# LPC111x/LPC11Cxx/LPC11xxL/LPC11xxXL register map
File version: 6
CPU: CM0 r0p0, little endian, no MPU, no FPU, 2 interrupt priority bits
Registers are 32-bit, read-write, reset 0x0 unless marked. A register's access mark holds for its fields unless they carry their own. Offsets are from the block's base; [hi:lo] are bit positions; {n}, {i} and the like mark numbered series.

## FLASHCTRL — Flash Programming Firmware
Base 0x4003C000
0x10 FLASHCFG reset not defined — Flash memory access time configuration register
  [1:0] FLASHTIM — Flash memory access time. FLASHTIM +1 is equal to the number of system clocks used for flash access.
    1=1_SYSTEM_CLOCK_FLASH (1 system clock flash access time (for system clock frequencies of up to 20 MHz)); 2=2_SYSTEM_CLOCKS_FLAS (2 system clocks flash access time (for system clock frequencies of up to 40 MHz)); 3=3_SYSTEM_CLOCKS_FLAS (3 system clocks flash access time (for system clock frequencies of up to 50 MHz))
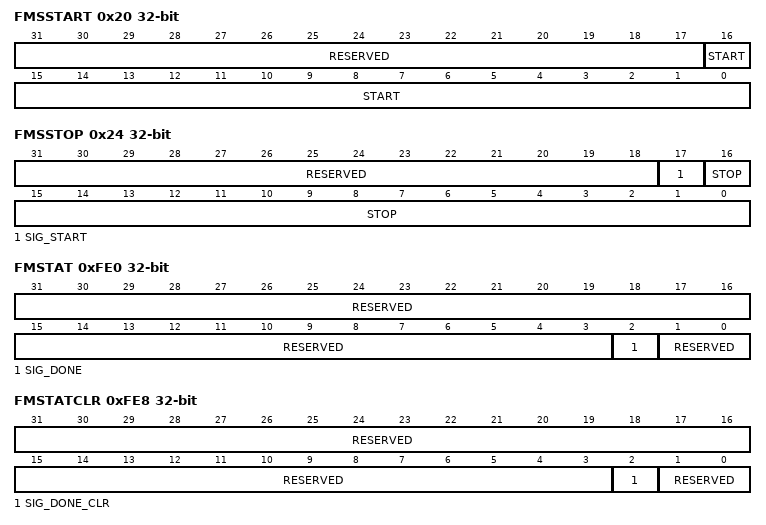
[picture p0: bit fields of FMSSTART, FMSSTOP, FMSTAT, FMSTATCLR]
0x20 FMSSTART — Signature start address register
  [31:17] RESERVED — Reserved, user software should not write ones to reserved bits. The value read from a reserved bit is not defined.
  [16:0] START — Signature generation start address (corresponds to AHB byte address bits[20:4]).
0x24 FMSSTOP — Signature stop-address register
  [31:18] RESERVED — Reserved, user software should not write ones to reserved bits. The value read from a reserved bit is not defined.
  [17] SIG_START — Start control bit for signature generation.
    0=SIGNATURE_GENERATION (Signature generation is stopped); 1=INITIATE_SIGNATURE_G (Initiate signature generation)
  [16:0] STOP — BIST stop address divided by 16 (corresponds to AHB byte address [20:4]).
{0x2C+4i} FMSW{i} ro reset not defined (i=0..3) — Word {i} [{32i+31}:{32i}]
  [31:0] SW{i}_{32i+31}_{32i} — Word {i} of 128-bit signature (bits {32i+31} to {32i}).
0xFE0 FMSTAT ro — Signature generation status register
  [31:3] RESERVED — Reserved, user software should not write ones to reserved bits. The value read from a reserved bit is not defined.
  [2] SIG_DONE — When 1, a previously started signature generation has completed. See FMSTATCLR register description for clearing this flag.
  [1:0] RESERVED — Reserved, user software should not write ones to reserved bits. The value read from a reserved bit is not defined.
0xFE8 FMSTATCLR wo reset not defined — Signature generation status clear register
  [31:3] RESERVED — Reserved, user software should not write ones to reserved bits. The value read from a reserved bit is not defined.
  [2] SIG_DONE_CLR — Writing a 1 to this bits clears the signature generation completion flag (SIG_DONE) in the FMSTAT register.
  [1:0] RESERVED — Reserved, user software should not write ones to reserved bits. The value read from a reserved bit is not defined.

## GPIO0 — General Purpose I/O
Base 0x50000000
Same registers: GPIO1 0x50010000, GPIO2 0x50020000, GPIO3 0x50030000
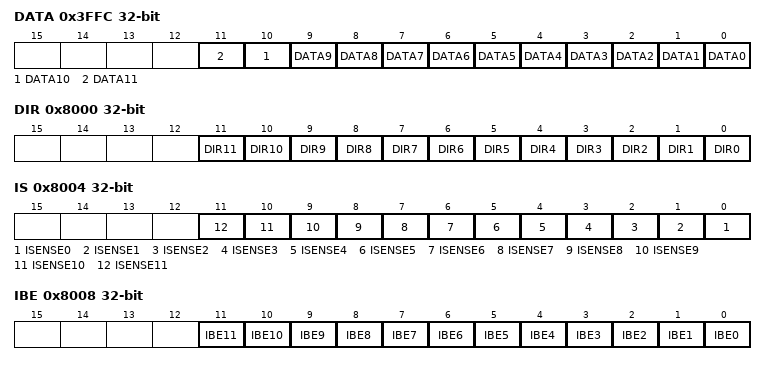
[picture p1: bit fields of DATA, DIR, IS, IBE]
0x3FFC DATA reset not defined
  [all] fields
    0=LOW (Pin is driven low); 1=HIGH (Pin is driven high)
  [n] DATA{n} (n=0..11) — PIOn_{n}.
0x8000 DIR — Data direction register
  [all] fields
    0=INPUT (Pin is configured as an input); 1=OUTPUT (Pin is configured as an output)
  [n] DIR{n} (n=0..11) — PIOn_{n}.
0x8004 IS — Interrupt sense register
  [all] fields
    0=EDGE (Pin interrupt is edge-sensitive); 1=LEVEL (Pin interrupt is level-sensitive)
  [n] ISENSE{n} (n=0..11) — PIOn_{n}.
0x8008 IBE — Interrupt both-edges register
  [all] fields
    0=IEV (Pin interrupt edge is configured through the IEV register); 1=BOTH (Pin interrupt is triggered on both rising and falling edges (if edge-sensitive))
  [n] IBE{n} (n=0..11) — PIOn_{n}.
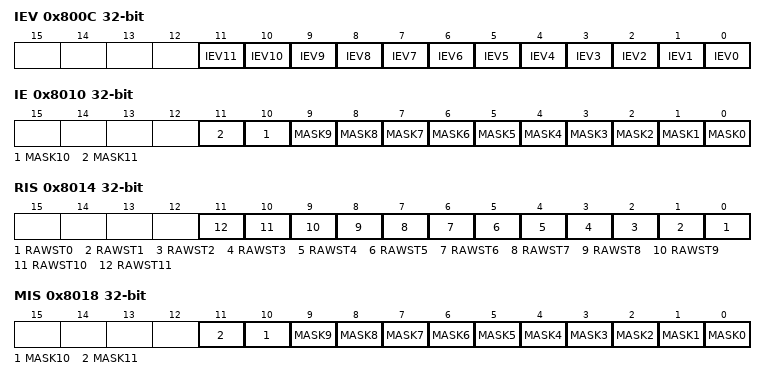
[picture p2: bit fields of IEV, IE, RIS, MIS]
0x800C IEV — Interrupt event register
  [all] fields
    0=FALLING (Pin interrupt is triggered on falling edges (if edge-sensitive)); 1=RISING (Pin interrupt is triggered on rising edges (if edge-sensitive))
  [n] IEV{n} (n=0..11) — PIOn_{n}.
0x8010 IE — Interrupt mask register
  [n] MASK{n} (n=0..11) — PIOn_{n}.
0x8014 RIS ro — Raw interrupt status register
  [n] RAWST{n} (n=0..11) — PIOn_{n}.
0x8018 MIS ro — Masked interrupt status register
  [n] MASK{n} (n=0..11) — PIOn_{n}.
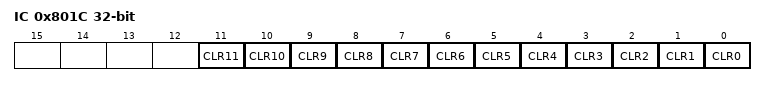
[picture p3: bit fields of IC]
0x801C IC wo — Interrupt clear register
  [all] fields
    1=CLEAR_INTERRUPT (Clear pin interrupt.)
  [n] CLR{n} (n=0..11) — PIOn_{n}.
